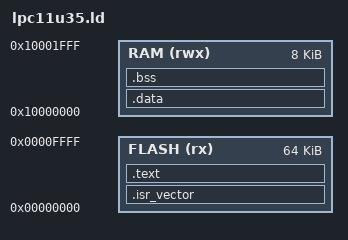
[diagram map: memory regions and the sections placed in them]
MEMORY
{
    FLASH (rx) : ORIGIN = 0x00000000, LENGTH = 64K
    RAM (rwx)  : ORIGIN = 0x10000000, LENGTH = 8K
}

_estack = ORIGIN(RAM) + LENGTH(RAM);

SECTIONS
{
    .isr_vector :
    {
        . = ALIGN(4);
        KEEP(*(.isr_vector))
        . = ALIGN(4);
    } > FLASH

    .text :
    {
        . = ALIGN(4);
        *(.text)
        *(.text*)
        *(.rodata)
        *(.rodata*)
        . = ALIGN(4);
        _etext = .;
    } > FLASH

    .data : AT(_etext)
    {
        . = ALIGN(4);
        _sdata = .;
        *(.data)
        *(.data*)
        . = ALIGN(4);
        _edata = .;
    } > RAM

    _sidata = LOADADDR(.data);

    .bss :
    {
        . = ALIGN(4);
        _sbss = .;
        *(.bss)
        *(.bss*)
        *(COMMON)
        . = ALIGN(4);
        _ebss = .;
    } > RAM
}
